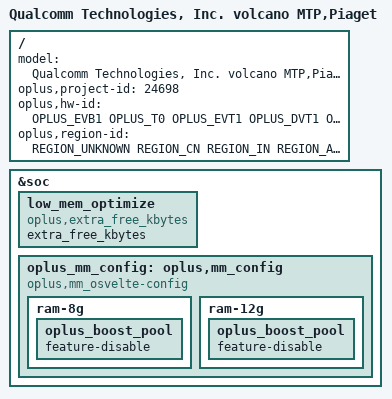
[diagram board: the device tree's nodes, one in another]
/dts-v1/;
/plugin/;
#include "piaget_24698_common.dtsi"
#include "nfc/piaget-nfc-thn31f.dtsi"
#include "region-id.h.dtsi"
#include "oplus_chg/oplus-chg-24697.dtsi"
#include "oplus_chg/pps/oplus-chg-piaget-pps.dtsi"

/ {
    model = "Qualcomm Technologies, Inc. volcano MTP,Piaget";

    oplus,project-id = <24698>;
    oplus,hw-id = <OPLUS_EVB1 OPLUS_T0 OPLUS_EVT1 OPLUS_DVT1 OPLUS_PVT1>;
    oplus,region-id = <REGION_UNKNOWN REGION_CN REGION_IN REGION_APAC REGION_JP REGION_US>;
};

&soc {
/* Add for low_mem_optimize */
    low_mem_optimize {
        compatible = "oplus,extra_free_kbytes";
        extra_free_kbytes;
    };
    oplus_mm_config: oplus,mm_config {
        compatible = "oplus,mm_osvelte-config";
    ram-8g{
        oplus_boost_pool {
            feature-disable;
        };
    };
    ram-12g {
        oplus_boost_pool {
            feature-disable;
        };
    };
    };
};
